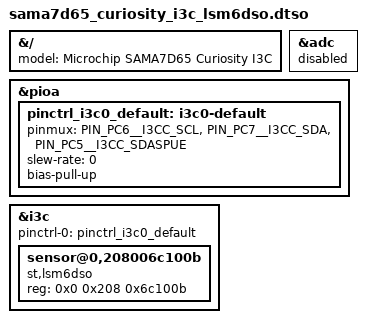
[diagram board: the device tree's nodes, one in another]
// SPDX-License-Identifier: (GPL-2.0+ OR MIT)
/*
 *  Device Tree overlay for SAMA7D65-CURIOSITY board
 *  in order to use LSM6DSO IMU sensor.
 *
 *  Copyright (c) 2025 Microchip Technology Inc. and its subsidiaries
 *
 *  Author: Durai Manickam KR <durai.manickamkr@microchip.com>
 *
 */
/dts-v1/;
/plugin/;
#include "sama7d65-pinfunc.h"
#include <dt-bindings/clock/at91.h>
#include <dt-bindings/pinctrl/at91.h>
#include <dt-bindings/gpio/gpio.h>
#include <dt-bindings/interrupt-controller/irq.h>

&{/}
{
	model = "Microchip SAMA7D65 Curiosity I3C";
};

&adc {
	status = "disabled";
};

&pioa {
	pinctrl_i3c0_default: i3c0-default {
		pinmux = <PIN_PC6__I3CC_SCL>,
			 <PIN_PC7__I3CC_SDA>,
			 <PIN_PC5__I3CC_SDASPUE>;
		slew-rate = <0>;
		bias-pull-up;
	};
};

&i3c {
	#address-cells = <3>;
	#size-cells = <0>;
	pinctrl-names = "default";
        pinctrl-0 = <&pinctrl_i3c0_default>;
	status = "okay";

	sensor@0,208006c100b {
		compatible = "st,lsm6dso";
		reg = <0x0 0x208 0x6c100b>;
	};
};
